# STM32L496ZGT7P register map
File version: 1.0
Registers are 32-bit, access not given, reset 0x0 unless marked. A register's access mark holds for its fields unless they carry their own. Offsets are from the block's base; [hi:lo] are bit positions; {n}, {i} and the like mark numbered series; 'fields as' and 'values as' point back to an identical list.

## SAI1
Base 0x40015400
Same registers: SAI2 0x40015800
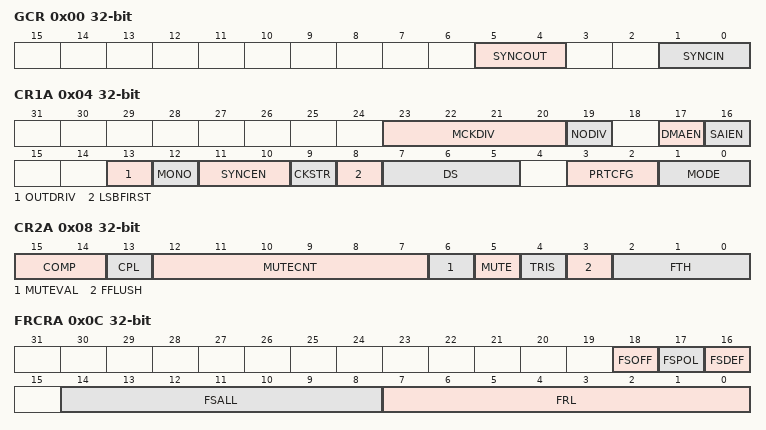
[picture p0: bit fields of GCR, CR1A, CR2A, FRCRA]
0x00 GCR
  [5:4] SYNCOUT, [1:0] SYNCIN
0x04 CR1A
  [23:20] MCKDIV, [19] NODIV, [17] DMAEN, [16] SAIEN, [13] OUTDRIV, [12] MONO, [11:10] SYNCEN, [9] CKSTR, [8] LSBFIRST, [7:5] DS, [3:2] PRTCFG, [1:0] MODE
0x08 CR2A
  [15:14] COMP, [13] CPL, [12:7] MUTECNT, [6] MUTEVAL, [5] MUTE, [4] TRIS, [3] FFLUSH, [2:0] FTH
0x0C FRCRA
  [18] FSOFF, [17] FSPOL, [16] FSDEF, [14:8] FSALL, [7:0] FRL
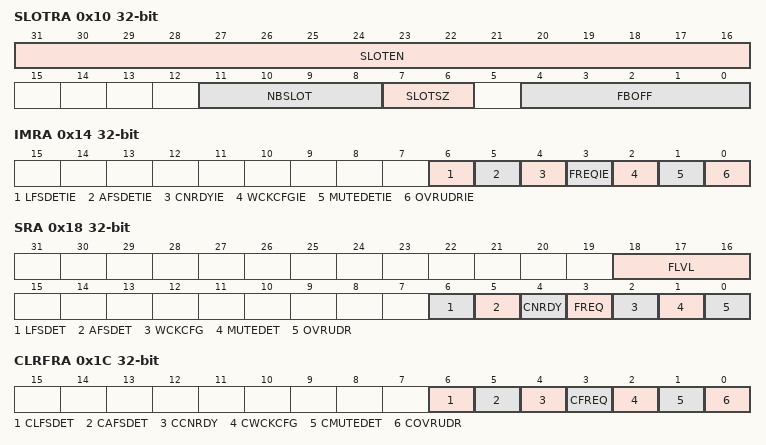
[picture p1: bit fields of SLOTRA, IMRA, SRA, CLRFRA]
0x10 SLOTRA
  [31:16] SLOTEN, [11:8] NBSLOT, [7:6] SLOTSZ, [4:0] FBOFF
0x14 IMRA
  [6] LFSDETIE, [5] AFSDETIE, [4] CNRDYIE, [3] FREQIE, [2] WCKCFGIE, [1] MUTEDETIE, [0] OVRUDRIE
0x18 SRA
  [18:16] FLVL, [6] LFSDET, [5] AFSDET, [4] CNRDY, [3] FREQ, [2] WCKCFG, [1] MUTEDET, [0] OVRUDR
0x1C CLRFRA
  [6] CLFSDET, [5] CAFSDET, [4] CCNRDY, [3] CFREQ, [2] CWCKCFG, [1] CMUTEDET, [0] COVRUDR
0x20 DRA
  [31:0] DATA
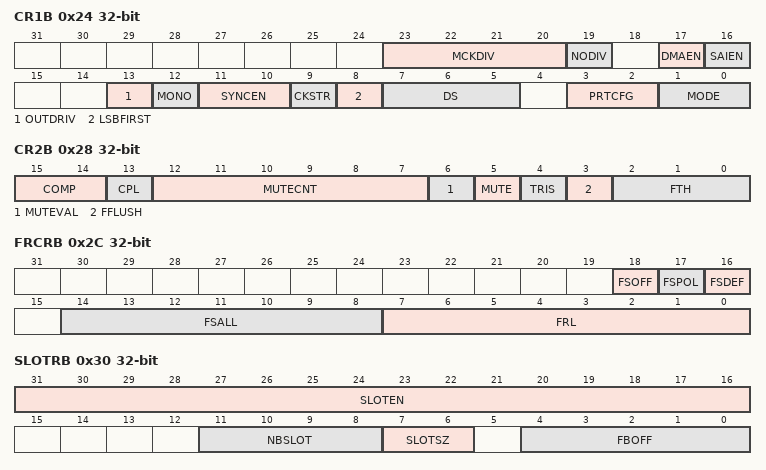
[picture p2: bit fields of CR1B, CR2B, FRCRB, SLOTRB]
0x24 CR1B
  fields as CR1A
0x28 CR2B
  fields as CR2A
0x2C FRCRB
  [18] FSOFF, [17] FSPOL, [16] FSDEF, [14:8] FSALL, [7:0] FRL
0x30 SLOTRB
  [31:16] SLOTEN, [11:8] NBSLOT, [7:6] SLOTSZ, [4:0] FBOFF
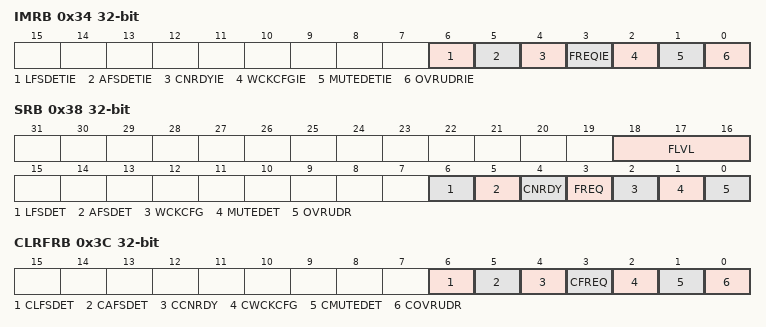
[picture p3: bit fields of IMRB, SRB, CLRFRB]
0x34 IMRB
  fields as IMRA
0x38 SRB
  fields as SRA
0x3C CLRFRB
  fields as CLRFRA
0x40 DRB
  [31:0] DATA

## DFSDM1
Base 0x40016000
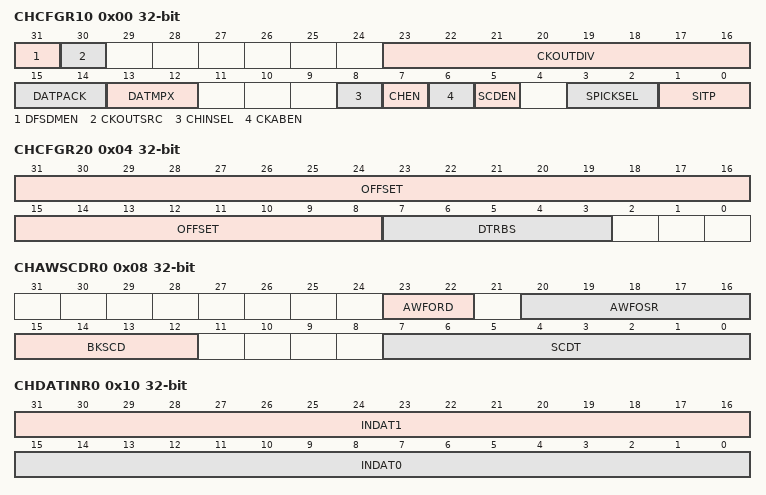
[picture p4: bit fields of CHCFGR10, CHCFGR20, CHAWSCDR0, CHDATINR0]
0x00 CHCFGR10
  [31] DFSDMEN, [30] CKOUTSRC, [23:16] CKOUTDIV, [15:14] DATPACK, [13:12] DATMPX, [8] CHINSEL, [7] CHEN, [6] CKABEN, [5] SCDEN, [3:2] SPICKSEL, [1:0] SITP
0x04 CHCFGR20
  [31:8] OFFSET, [7:3] DTRBS
0x08 CHAWSCDR0
  [23:22] AWFORD, [20:16] AWFOSR, [15:12] BKSCD, [7:0] SCDT
0x0C CHWDATAR0
0x10 CHDATINR0
  [31:16] INDAT1, [15:0] INDAT0
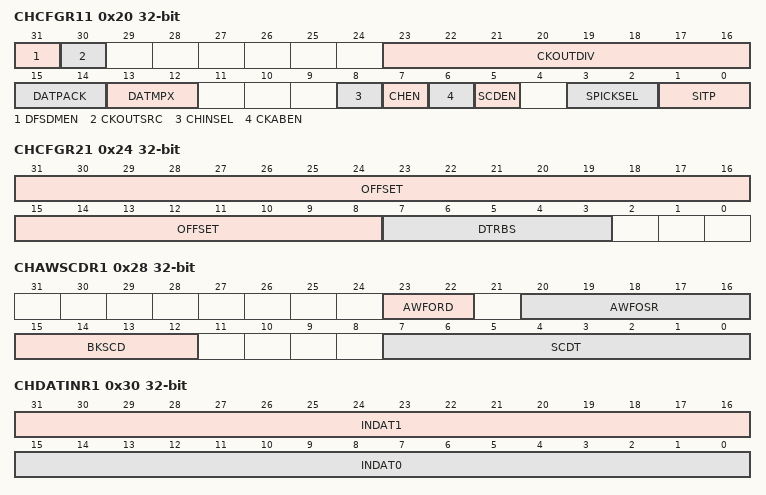
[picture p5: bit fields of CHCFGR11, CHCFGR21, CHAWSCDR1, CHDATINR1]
0x20 CHCFGR11
  fields as CHCFGR10
0x24 CHCFGR21
  [31:8] OFFSET, [7:3] DTRBS
0x28 CHAWSCDR1
  [23:22] AWFORD, [20:16] AWFOSR, [15:12] BKSCD, [7:0] SCDT
0x2C CHWDATAR1
0x30 CHDATINR1
  [31:16] INDAT1, [15:0] INDAT0
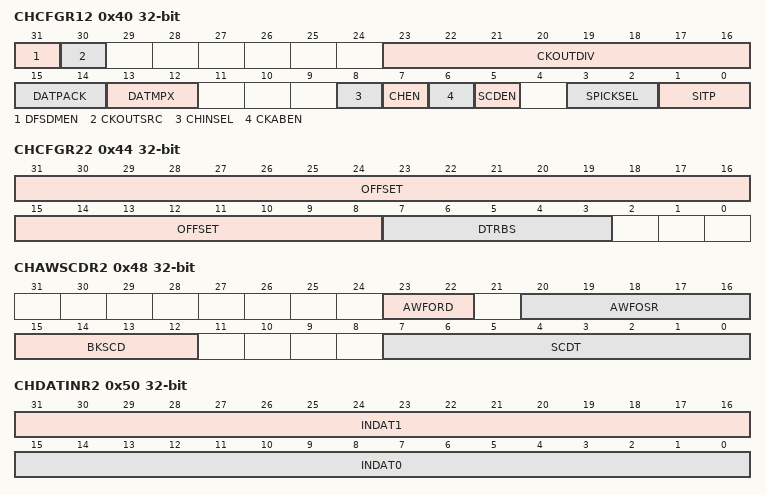
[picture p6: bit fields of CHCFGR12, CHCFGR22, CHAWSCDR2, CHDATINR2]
0x40 CHCFGR12
  fields as CHCFGR10
0x44 CHCFGR22
  [31:8] OFFSET, [7:3] DTRBS
0x48 CHAWSCDR2
  [23:22] AWFORD, [20:16] AWFOSR, [15:12] BKSCD, [7:0] SCDT
0x4C CHWDATAR2
0x50 CHDATINR2
  [31:16] INDAT1, [15:0] INDAT0
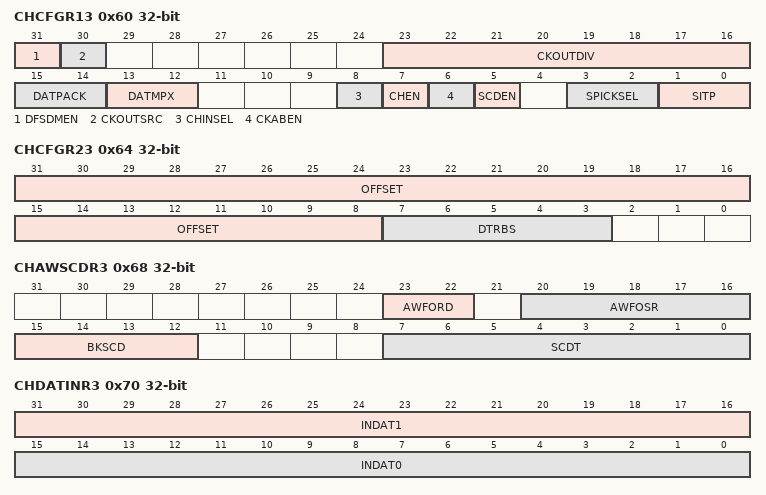
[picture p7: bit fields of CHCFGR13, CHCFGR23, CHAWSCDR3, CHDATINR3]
0x60 CHCFGR13
  fields as CHCFGR10
0x64 CHCFGR23
  [31:8] OFFSET, [7:3] DTRBS
0x68 CHAWSCDR3
  [23:22] AWFORD, [20:16] AWFOSR, [15:12] BKSCD, [7:0] SCDT
0x6C CHWDATAR3
0x70 CHDATINR3
  [31:16] INDAT1, [15:0] INDAT0
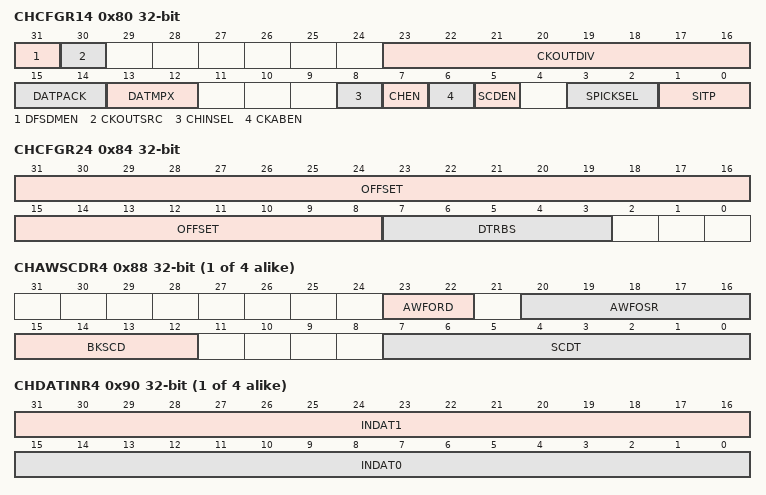
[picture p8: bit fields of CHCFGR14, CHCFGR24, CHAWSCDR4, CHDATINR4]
0x80 CHCFGR14
  fields as CHCFGR10
0x84 CHCFGR24
  [31:8] OFFSET, [7:3] DTRBS
{0x8+0x20*i} CHAWSCDR{i} (i=4..7)
  [23:22] AWFORD, [20:16] AWFOSR, [15:12] BKSCD, [7:0] SCDT
{0xC+0x20*i} CHWDATAR{i} (i=4..7)
{0x10+0x20*i} CHDATINR{i} (i=4..7)
  [31:16] INDAT1, [15:0] INDAT0
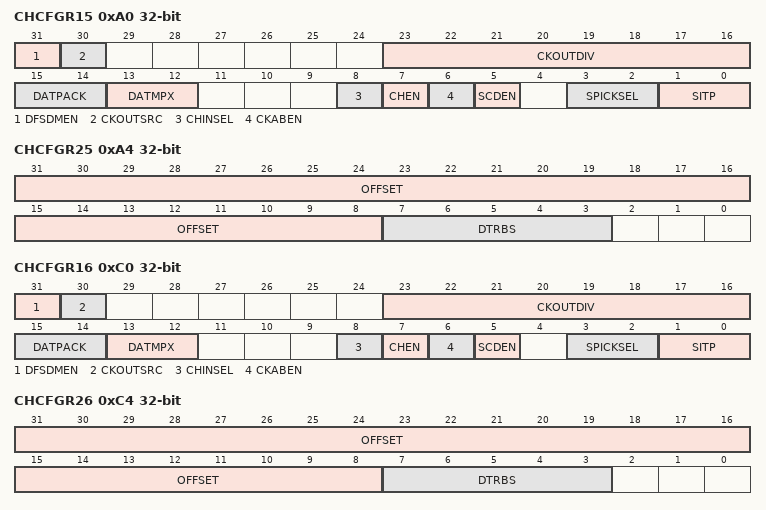
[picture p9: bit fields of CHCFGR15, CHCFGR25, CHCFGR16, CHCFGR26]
0xA0 CHCFGR15
  fields as CHCFGR10
0xA4 CHCFGR25
  [31:8] OFFSET, [7:3] DTRBS
0xC0 CHCFGR16
  fields as CHCFGR10
0xC4 CHCFGR26
  [31:8] OFFSET, [7:3] DTRBS
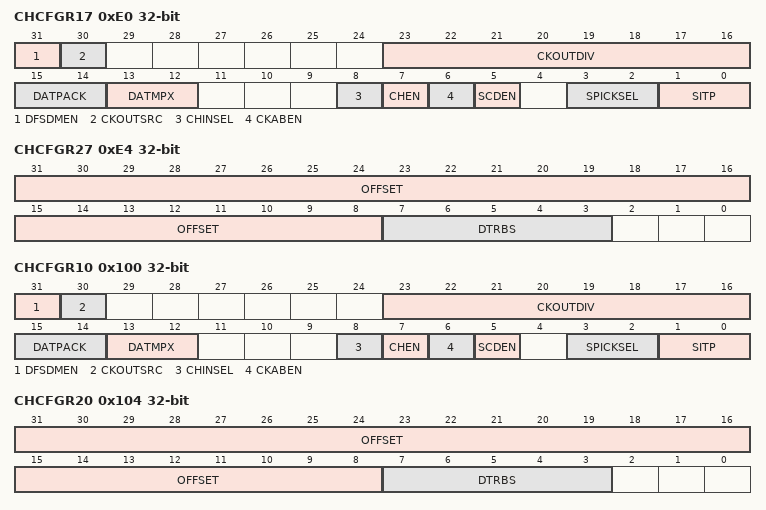
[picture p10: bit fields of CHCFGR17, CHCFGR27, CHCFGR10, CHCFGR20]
0xE0 CHCFGR17
  fields as CHCFGR10
0xE4 CHCFGR27
  [31:8] OFFSET, [7:3] DTRBS
0x100 CHCFGR10
  fields as CHCFGR10
0x104 CHCFGR20
  [31:8] OFFSET, [7:3] DTRBS
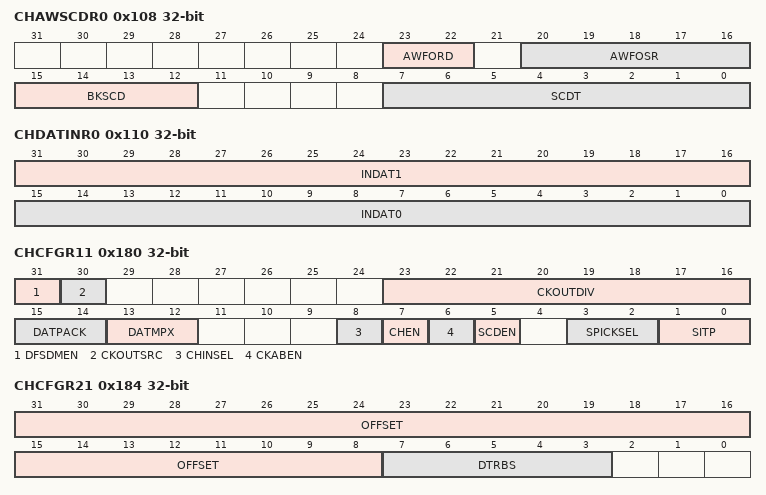
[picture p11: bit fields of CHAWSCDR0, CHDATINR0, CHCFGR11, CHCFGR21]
0x108 CHAWSCDR0
  [23:22] AWFORD, [20:16] AWFOSR, [15:12] BKSCD, [7:0] SCDT
0x10C CHWDATAR0
0x110 CHDATINR0
  [31:16] INDAT1, [15:0] INDAT0
0x180 CHCFGR11
  fields as CHCFGR10
0x184 CHCFGR21
  [31:8] OFFSET, [7:3] DTRBS
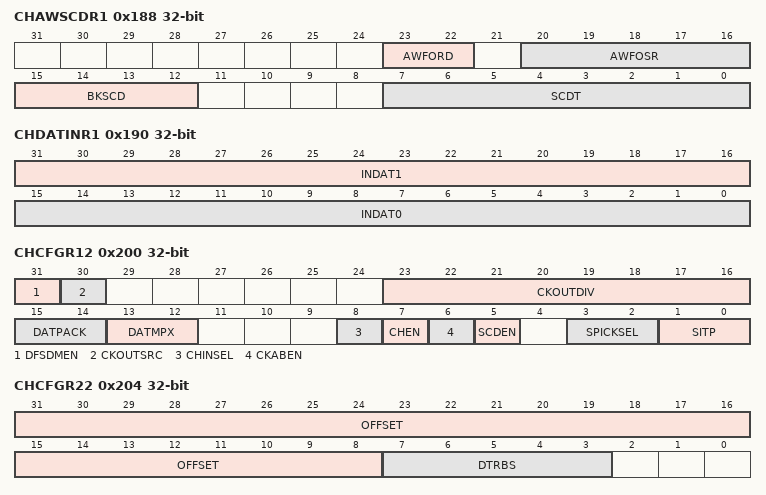
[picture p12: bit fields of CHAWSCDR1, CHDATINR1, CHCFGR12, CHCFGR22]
0x188 CHAWSCDR1
  [23:22] AWFORD, [20:16] AWFOSR, [15:12] BKSCD, [7:0] SCDT
0x18C CHWDATAR1
0x190 CHDATINR1
  [31:16] INDAT1, [15:0] INDAT0
0x200 CHCFGR12
  fields as CHCFGR10
0x204 CHCFGR22
  [31:8] OFFSET, [7:3] DTRBS
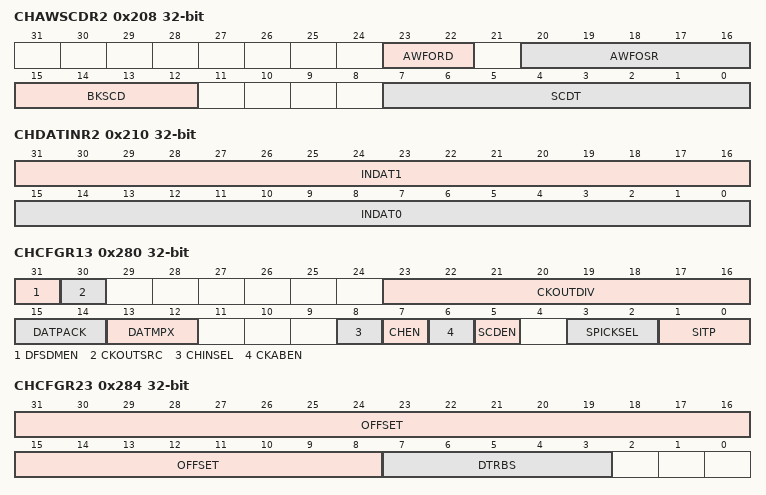
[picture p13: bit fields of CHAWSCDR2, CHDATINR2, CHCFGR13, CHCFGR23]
0x208 CHAWSCDR2
  [23:22] AWFORD, [20:16] AWFOSR, [15:12] BKSCD, [7:0] SCDT
0x20C CHWDATAR2
0x210 CHDATINR2
  [31:16] INDAT1, [15:0] INDAT0
0x280 CHCFGR13
  fields as CHCFGR10
0x284 CHCFGR23
  [31:8] OFFSET, [7:3] DTRBS
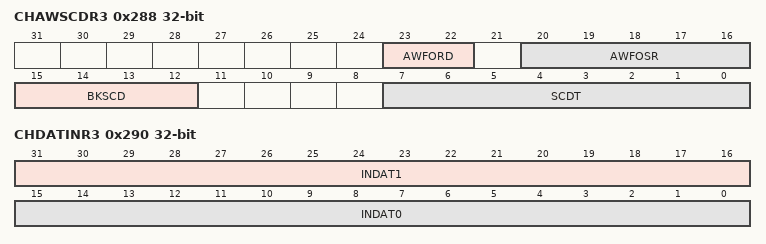
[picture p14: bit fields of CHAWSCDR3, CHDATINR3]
0x288 CHAWSCDR3
  [23:22] AWFORD, [20:16] AWFOSR, [15:12] BKSCD, [7:0] SCDT
0x28C CHWDATAR3
0x290 CHDATINR3
  [31:16] INDAT1, [15:0] INDAT0

## DMA1
Base 0x40020000
Same registers: DMA2 0x40020400
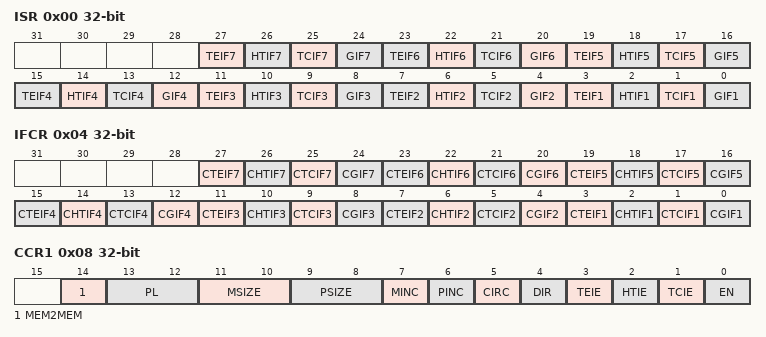
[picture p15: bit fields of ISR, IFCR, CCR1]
0x00 ISR
  [4n-1] TEIF{n} (n=1..7), [4n-2] HTIF{n} (n=1..7), [4n-3] TCIF{n} (n=1..7), [4n-4] GIF{n} (n=1..7)
0x04 IFCR
  [4n-1] CTEIF{n} (n=1..7), [4n-2] CHTIF{n} (n=1..7), [4n-3] CTCIF{n} (n=1..7), [4n-4] CGIF{n} (n=1..7)
0x08 CCR1
  [14] MEM2MEM, [13:12] PL, [11:10] MSIZE, [9:8] PSIZE, [7] MINC, [6] PINC, [5] CIRC, [4] DIR, [3] TEIE, [2] HTIE, [1] TCIE, [0] EN
0x0C CNDTR1
  [15:0] NDT
0x10 CPAR1
  [31:0] PA
{0x0+0x14*i} CMAR{i} (i=1..7)
  [31:0] MA
0x1C CCR2
  fields as CCR1
0x20 CNDTR2
  [15:0] NDT
0x24 CPAR2
  [31:0] PA
0x30 CCR3
  fields as CCR1
0x34 CNDTR3
  [15:0] NDT
0x38 CPAR3
  [31:0] PA
0x44 CCR4
  fields as CCR1
0x48 CNDTR4
  [15:0] NDT
0x4C CPAR4
  [31:0] PA
0x58 CCR5
  fields as CCR1
0x5C CNDTR5
  [15:0] NDT
0x60 CPAR5
  [31:0] PA
0x6C CCR6
  fields as CCR1
0x70 CNDTR6
  [15:0] NDT
0x74 CPAR6
  [31:0] PA
0x80 CCR7
  fields as CCR1
0x84 CNDTR7
  [15:0] NDT
0x88 CPAR7
  [31:0] PA
